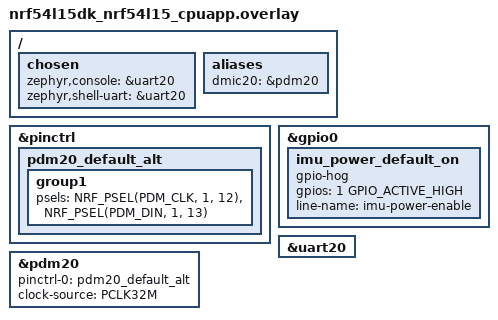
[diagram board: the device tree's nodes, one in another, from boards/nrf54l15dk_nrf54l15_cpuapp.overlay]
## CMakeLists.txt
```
# SPDX-License-Identifier: Apache-2.0

cmake_minimum_required(VERSION 3.20.0)

# Find Zephyr
find_package(Zephyr REQUIRED HINTS $ENV{ZEPHYR_BASE})

# Create project
project(voice_bridge_ble)

# Target sources
target_sources(app PRIVATE
    src/main.c
    src/adpcm.c
    src/audio_capture.c
)
```

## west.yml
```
manifest:
  version: 1.0

  defaults:
    remote: upstream
    revision: v4.0.0

  remotes:
    - name: upstream
      url-base: https://github.com/zephyrproject-rtos

  projects:
    - name: zephyr
      repo-path: zephyr
      path: zephyr
      import:
        name-allowlist:
          - hal_nordic
          - mcuboot
          - trusted-firmware-m

  self:
    path: nrf54l15
```

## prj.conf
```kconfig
# Zephyr Kernel Configuration for Voice Bridge BLE
# nRF54L15 Sense - BLE with PDM Microphone

# General System
CONFIG_MAIN_STACK_SIZE=4096
CONFIG_HEAP_MEM_POOL_SIZE=49152
CONFIG_SYS_CLOCK_TICKS_PER_SEC=32768

# Logging & Console
CONFIG_LOG=y
CONFIG_LOG_MODE_DEFERRED=n
CONFIG_CONSOLE=y
CONFIG_UART_CONSOLE=y
CONFIG_PRINTK=y

# Bluetooth Low Energy
CONFIG_BT=y
CONFIG_BT_PERIPHERAL=y
CONFIG_BT_BROADCASTER=y
CONFIG_BT_MAX_CONN=2
CONFIG_BT_SMP=n
CONFIG_BT_GATT_DYNAMIC_DB=y
CONFIG_BT_DEVICE_NAME="VoiceBridge"
CONFIG_BT_DEVICE_NAME_DYNAMIC=y
CONFIG_BT_DEVICE_NAME_MAX=20

# GATT client (for MTU exchange)
CONFIG_BT_GATT_CLIENT=y

# MTU extension for audio throughput
CONFIG_BT_L2CAP_TX_MTU=247
CONFIG_BT_BUF_ACL_RX_SIZE=251
CONFIG_BT_BUF_ACL_TX_SIZE=251
CONFIG_BT_CTLR_DATA_LENGTH_MAX=251

# Multiple TX buffers for throughput
CONFIG_BT_L2CAP_TX_BUF_COUNT=10
CONFIG_BT_ATT_TX_COUNT=10
CONFIG_BT_CONN_TX_MAX=10

# GPIO
CONFIG_GPIO=y
CONFIG_GPIO_NRFX=y

# PDM Microphone (DMIC)
CONFIG_AUDIO=y
CONFIG_AUDIO_DMIC=y
CONFIG_PINCTRL=y
```

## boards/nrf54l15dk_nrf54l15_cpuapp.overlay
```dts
/*
 * Device Tree Overlay for Voice Bridge BLE
 * PDM Microphone on XIAO nRF54L15 Sense
 * PDM_CLK: P1.12, PDM_DATA: P1.13
 */

#include <dt-bindings/gpio/gpio.h>

/ {
	chosen {
		zephyr,console = &uart20;
		zephyr,shell-uart = &uart20;
	};

	aliases {
		dmic20 = &pdm20;
	};
};

&pinctrl {
	pdm20_default_alt: pdm20_default_alt {
		group1 {
			psels = <NRF_PSEL(PDM_CLK, 1, 12)>,
				<NRF_PSEL(PDM_DIN, 1, 13)>;
		};
	};
};

&gpio0 {
	imu_power_default_on: imu_power_default_on {
		gpio-hog;
		gpios = <1 GPIO_ACTIVE_HIGH>;
		line-name = "imu-power-enable";
	};
};

&uart20 {
	status = "okay";
};

dmic_dev: &pdm20 {
	status = "okay";
	pinctrl-0 = <&pdm20_default_alt>;
	pinctrl-names = "default";
	clock-source = "PCLK32M";
};
```

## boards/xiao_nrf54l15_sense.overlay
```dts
/*
 * Device Tree Overlay for Seeed Studio XIAO nRF54L15 Sense
 * Voice Bridge BLE - PDM Microphone Configuration
 */

#include <dt-bindings/gpio/gpio.h>

/ {
    chosen {
        zephyr,console = &uart20;
        zephyr,shell-uart = &uart20;
    };

    aliases {
        dmic20 = &pdm20;
    };
};

&pinctrl {
    pdm20_default_alt: pdm20_default_alt {
        group1 {
            psels = <NRF_PSEL(PDM_CLK, 1, 12)>,
                    <NRF_PSEL(PDM_DIN, 1, 13)>;
        };
    };
};

&gpio0 {
    imu_power_default_on: imu_power_default_on {
        gpio-hog;
        gpios = <1 GPIO_ACTIVE_HIGH>;
        line-name = "imu-power-enable";
    };
};

/* PDM instance 20 for onboard DMIC microphone */
&pdm20 {
    status = "okay";
    pinctrl-0 = <&pdm20_default_alt>;
    pinctrl-names = "default";
    clock-source = "PCLK32M";
};

&uart20 {
    status = "okay";
};
```

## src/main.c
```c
/*
 * Voice Bridge BLE - XIAO nRF54L15 Sense
 * PDM Microphone to Mac via BLE
 */

#include <zephyr/kernel.h>
#include <zephyr/logging/log.h>
#include <zephyr/bluetooth/bluetooth.h>
#include <zephyr/bluetooth/conn.h>
#include <zephyr/bluetooth/uuid.h>
#include <zephyr/bluetooth/gatt.h>
#include <string.h>

#include "audio_capture.h"

LOG_MODULE_REGISTER(voice_bridge, LOG_LEVEL_INF);

/* ============================================================================
 * Configuration
 * ============================================================================ */

#define BLE_DEVICE_NAME     "VoiceBridge"

/* Recording packet size */
#define PCM_PACKET_SIZE     200

/* ============================================================================
 * BLE UUIDs (Same as ESP32/nRF52840 version for compatibility)
 * ============================================================================ */

/* Custom Service UUID: 00000001-0000-1000-8000-00805f9b34fb */
#define LBS_UUID_SERVICE \
    0xfb, 0x34, 0x9b, 0x5f, 0x80, 0x00, 0x00, 0x80, \
    0x00, 0x10, 0x00, 0x00, 0x01, 0x00, 0x00, 0x00

/* TX Characteristic UUID: 00000002-0000-1000-8000-00805f9b34fb (Notify) */
#define LBS_UUID_TX_CHAR \
    0xfb, 0x34, 0x9b, 0x5f, 0x80, 0x00, 0x00, 0x80, \
    0x00, 0x10, 0x00, 0x00, 0x02, 0x00, 0x00, 0x00

/* RX Characteristic UUID: 00000003-0000-1000-8000-00805f9b34fb (Write) */
#define LBS_UUID_RX_CHAR \
    0xfb, 0x34, 0x9b, 0x5f, 0x80, 0x00, 0x00, 0x80, \
    0x00, 0x10, 0x00, 0x00, 0x03, 0x00, 0x00, 0x00

/* ============================================================================
 * Global Variables
 * ============================================================================ */

static struct bt_conn *current_conn;

static uint8_t tx_packet[512];  /* PCM frame + 2-byte header */
static uint8_t seq_num = 0;

/* Recording state */
static volatile bool is_recording = false;
static volatile bool recording_requested = false;
static volatile bool stop_requested = false;

/* Audio thread */
static K_THREAD_STACK_DEFINE(audio_stack, 4096);
static struct k_thread audio_thread_data;
static void stream_audio_frame(const int16_t *audio_buffer, size_t audio_size);

static void generate_simulated_audio(int16_t *buffer, size_t sample_count)
{
    static uint32_t phase;
    const uint32_t freq = 440;
    const uint32_t sample_rate = audio_capture_get_sample_rate();

    for (size_t i = 0; i < sample_count; i++) {
        int32_t angle = (phase & 0xFFFF) * 360 / 0x10000;
        int32_t sample;

        if (angle < 90) {
            sample = angle * angle / 81;
        } else if (angle < 180) {
            sample = 16384 - (angle - 90) * (angle - 90) / 81;
        } else if (angle < 270) {
            sample = -(angle - 180) * (angle - 180) / 81;
        } else {
            sample = -16384 + (angle - 270) * (angle - 270) / 81;
        }

        buffer[i] = (int16_t)(sample * 2);
        phase += (freq * 0x10000) / sample_rate;
    }
}

/* ============================================================================
 * BLE GATT Service
 * ============================================================================ */

/* TX Value Changed Callback */
static void tx_ccc_cfg_changed(const struct bt_gatt_attr *attr, uint16_t value)
{
    LOG_INF("TX CCCD updated: %d", value);
    printk(">>> CCCD updated: %d (1=notify enabled)\n", value);
}

/* RX Write Callback */
static ssize_t rx_write(struct bt_conn *conn, const struct bt_gatt_attr *attr,
                        const void *buf, uint16_t len, uint16_t offset,
                        uint8_t flags)
{
    const uint8_t *data = buf;

    LOG_INF("Received command: len=%d", len);
    printk(">>> RX write: len=%d\n", len);

    if (len >= 1) {
        if (data[0] == 0x01) {
            LOG_INF("Start recording command");
            printk(">>> START recording command received\n");
            recording_requested = true;
        } else if (data[0] == 0x00) {
            LOG_INF("Stop recording command");
            printk(">>> STOP recording command received\n");
            stop_requested = true;
        }
    }

    return len;
}

/* GATT Service Definition */
BT_GATT_SERVICE_DEFINE(voice_bridge_svc,
    BT_GATT_PRIMARY_SERVICE(
        BT_UUID_DECLARE_128(LBS_UUID_SERVICE)),

    /* TX Characteristic (Notify) */
    BT_GATT_CHARACTERISTIC(
        BT_UUID_DECLARE_128(LBS_UUID_TX_CHAR),
        BT_GATT_CHRC_NOTIFY,
        BT_GATT_PERM_READ,
        NULL, NULL, NULL),
    BT_GATT_CCC(tx_ccc_cfg_changed,
                BT_GATT_PERM_READ | BT_GATT_PERM_WRITE),

    /* RX Characteristic (Write) */
    BT_GATT_CHARACTERISTIC(
        BT_UUID_DECLARE_128(LBS_UUID_RX_CHAR),
        BT_GATT_CHRC_WRITE,
        BT_GATT_PERM_WRITE,
        NULL, rx_write, NULL),
);

static void stream_audio_frame(const int16_t *audio_buffer, size_t audio_size)
{
    int ret;
    size_t total_samples = audio_size / sizeof(int16_t);
    size_t offset = 0;
    size_t packets_sent = 0;
    size_t notify_errors = 0;

    while (offset < total_samples) {
        size_t samples_to_send = total_samples - offset;

        if (samples_to_send > PCM_PACKET_SIZE / sizeof(int16_t)) {
            samples_to_send = PCM_PACKET_SIZE / sizeof(int16_t);
        }

        tx_packet[0] = seq_num++;
        tx_packet[1] = 0xAA;
        memcpy(&tx_packet[2], &audio_buffer[offset],
               samples_to_send * sizeof(int16_t));

        ret = bt_gatt_notify(NULL, &voice_bridge_svc.attrs[2],
                             tx_packet, 2 + (samples_to_send * sizeof(int16_t)));
        if (ret == -ENOMEM) {
            k_msleep(1);
            ret = bt_gatt_notify(NULL, &voice_bridge_svc.attrs[2],
                                 tx_packet, 2 + (samples_to_send * sizeof(int16_t)));
        }

        if (ret == 0) {
            packets_sent++;
        } else {
            notify_errors++;
            printk("!!! bt_gatt_notify error: %d\n", ret);
        }

        offset += samples_to_send;
        k_msleep(1);
    }

    printk("Audio: %zu samples, sent %zu packets, errors %zu\n",
           total_samples, packets_sent, notify_errors);
}

/* ============================================================================
 * Audio Streaming Thread
 * ============================================================================ */

static void audio_thread(void *p1, void *p2, void *p3)
{
    ARG_UNUSED(p1);
    ARG_UNUSED(p2);
    ARG_UNUSED(p3);

    int ret;
    int16_t *audio_buffer;
    size_t audio_size;
    bool dmic_available = false;
    bool dmic_session_active = false;
    static int16_t sim_buffer[320];

    printk("Audio thread started\n");

    /* Initialize audio capture */
    ret = audio_capture_init();
    if (ret < 0) {
        printk("Audio init failed: %d\n", ret);
        printk(">>> Using simulated audio data\n");
    } else {
        dmic_available = true;
        printk("Audio capture initialized\n");
    }

    while (1) {
        if (recording_requested && !is_recording) {
            recording_requested = false;
            stop_requested = false;
            seq_num = 0;

            if (dmic_available) {
                ret = audio_capture_start();
                if (ret < 0) {
                    printk("Audio start failed: %d\n", ret);
                    printk(">>> Falling back to simulated audio\n");
                    dmic_session_active = false;
                } else {
                    dmic_session_active = true;
                    printk("Audio capture running\n");
                }
            }

            is_recording = true;
            printk("Recording started\n");
        }

        if (stop_requested && is_recording) {
            stop_requested = false;
            is_recording = false;

            if (dmic_session_active) {
                ret = audio_capture_stop();
                if (ret < 0) {
                    printk("Audio stop failed: %d\n", ret);
                }
                dmic_session_active = false;
            }

            printk("Recording stopped\n");
        }

        if (is_recording && current_conn) {
            if (dmic_session_active) {
                ret = audio_capture_get_data(&audio_buffer, &audio_size);
                if (ret < 0) {
                    printk("Audio read failed: %d\n", ret);
                    printk(">>> Falling back to simulated audio\n");
                    (void)audio_capture_stop();
                    dmic_session_active = false;
                    continue;
                }
            } else {
                generate_simulated_audio(sim_buffer, ARRAY_SIZE(sim_buffer));
                audio_buffer = sim_buffer;
                audio_size = sizeof(sim_buffer);
            }

            stream_audio_frame(audio_buffer, audio_size);
            continue;
        }

        if (!current_conn && dmic_session_active) {
            (void)audio_capture_stop();
            dmic_session_active = false;
        }

        if (!is_recording) {
            k_msleep(20);
        } else {
            static int debug_count = 0;
            if (debug_count++ % 50 == 0 && !current_conn) {
                printk("DEBUG: Not connected (current_conn=NULL)\n");
            }
            k_msleep(20);
        }
    }
}

/* ============================================================================
 * BLE Connection Callbacks
 * ============================================================================ */

static void exchange_func(struct bt_conn *conn, uint8_t att_err,
                          struct bt_gatt_exchange_params *params)
{
    if (att_err) {
        LOG_ERR("MTU exchange failed: %d", att_err);
        printk(">>> MTU exchange failed: %d\n", att_err);
    } else {
        LOG_INF("MTU exchange done");
        printk(">>> MTU exchange done\n");
    }
}

static struct bt_gatt_exchange_params exchange_params = {
    .func = exchange_func,
};

static void connected(struct bt_conn *conn, uint8_t err)
{
    if (err) {
        LOG_ERR("Connection failed: %d", err);
        printk(">>> Connection failed: %d\n", err);
        return;
    }

    LOG_INF("Connected");
    printk(">>> Connected! current_conn set\n");
    current_conn = conn;

    /* Request MTU exchange */
    int ret = bt_gatt_exchange_mtu(conn, &exchange_params);
    if (ret) {
        LOG_ERR("MTU exchange request failed: %d", ret);
        printk(">>> MTU exchange failed: %d\n", ret);
    } else {
        printk(">>> MTU exchange requested\n");
    }

    /* Request short connection interval for audio throughput */
    struct bt_le_conn_param conn_param = {
        .interval_min = 6,   /* 7.5ms */
        .interval_max = 12,  /* 15ms */
        .latency = 0,
        .timeout = 400,      /* 4s */
    };
    ret = bt_conn_le_param_update(conn, &conn_param);
    if (ret) {
        LOG_WRN("Conn param update request failed: %d", ret);
        printk(">>> Conn param update failed: %d\n", ret);
    } else {
        printk(">>> Conn param update requested\n");
    }
}

static void disconnected(struct bt_conn *conn, uint8_t reason)
{
    LOG_INF("Disconnected: %d", reason);
    printk(">>> Disconnected: %d\n", reason);

    current_conn = NULL;

    is_recording = false;
    stop_requested = true;
}

static struct bt_conn_cb conn_callbacks = {
    .connected = connected,
    .disconnected = disconnected,
};

/* ============================================================================
 * Main Application
 * ============================================================================ */

int main(void)
{
    int ret;

    printk("\n");
    printk("============================================\n");
    printk("Voice Bridge BLE - XIAO nRF54L15 Sense\n");
    printk("============================================\n\n");
    printk("Starting firmware build: " __DATE__ " " __TIME__ "\n");

    LOG_INF("Starting Voice Bridge BLE");

    /* Initialize BLE (synchronous - pass NULL callback) */
    LOG_INF("Initializing BLE");
    ret = bt_enable(NULL);
    if (ret) {
        LOG_ERR("BLE enable failed: %d", ret);
        printk("!!! BLE enable failed: %d\n", ret);
        return ret;
    }

    LOG_INF("BLE initialized");
    printk("BLE initialized\n");

    /* Register connection callbacks */
    bt_conn_cb_register(&conn_callbacks);

    /* Set device name */
    ret = bt_set_name(BLE_DEVICE_NAME);
    if (ret) {
        LOG_ERR("Failed to set name: %d", ret);
        printk("!!! Failed to set name: %d\n", ret);
        return ret;
    }

    printk("Device name: %s\n", BLE_DEVICE_NAME);

    /* Start advertising */
    struct bt_data adv_data[] = {
        BT_DATA_BYTES(BT_DATA_FLAGS, BT_LE_AD_GENERAL | BT_LE_AD_NO_BREDR),
        BT_DATA_BYTES(BT_DATA_UUID128_ALL,
                     0xfb, 0x34, 0x9b, 0x5f, 0x80, 0x00, 0x00, 0x80,
                     0x00, 0x10, 0x00, 0x00, 0x01, 0x00, 0x00, 0x00),
    };

    struct bt_data scan_rsp[] = {
        BT_DATA(BT_DATA_NAME_COMPLETE, BLE_DEVICE_NAME, sizeof(BLE_DEVICE_NAME) - 1),
    };

    ret = bt_le_adv_start(BT_LE_ADV_CONN, adv_data, ARRAY_SIZE(adv_data),
                          scan_rsp, ARRAY_SIZE(scan_rsp));
    if (ret) {
        LOG_ERR("Advertising failed: %d", ret);
        printk("!!! Advertising failed: %d\n", ret);
        return ret;
    }

    LOG_INF("Advertising started: %s", BLE_DEVICE_NAME);
    printk("Advertising: %s\n", BLE_DEVICE_NAME);

    /* Start audio thread */
    /* Priority 14: lower than BLE stack (7) to avoid starving radio */
    k_thread_create(&audio_thread_data, audio_stack, K_THREAD_STACK_SIZEOF(audio_stack),
                    audio_thread, NULL, NULL, NULL, 14, 0, K_NO_WAIT);

    LOG_INF("Voice Bridge BLE ready");
    printk("System ready\n");

    /* Keep main thread alive */
    while (1) {
        k_sleep(K_SECONDS(1));
    }

    return 0;
}
```

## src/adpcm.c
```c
/*
 * ADPCM Codec Implementation
 * IMA ADPCM 4-bit encoding/decoding
 */

#include "adpcm.h"
#include <string.h>

/* IMA ADPCM step size table */
static const int32_t step_size_table[89] = {
    7, 8, 9, 10, 11, 12, 13, 14, 16, 17, 19, 21, 23, 25, 28, 31,
    34, 37, 41, 45, 50, 55, 60, 66, 73, 80, 88, 97, 107, 118, 130, 143,
    157, 173, 190, 209, 230, 253, 279, 307, 337, 371, 408, 449, 494, 544,
    598, 658, 724, 796, 876, 963, 1060, 1166, 1282, 1411, 1552, 1707, 1878,
    2066, 2272, 2499, 2749, 3024, 3327, 3660, 4026, 4428, 4871, 5358, 5894,
    6484, 7132, 7845, 8630, 9493, 10442, 11487, 12635, 13899, 15289, 16818,
    18500, 20350, 22385, 24623, 27086, 29794, 32767
};

/* Step size adjustment table for each ADPCM value */
static const int8_t step_adjust_table[8] = {
    -1, -1, -1, -1, 2, 4, 6, 8
};

static int32_t clamp(int32_t value, int32_t min, int32_t max)
{
    if (value < min) return min;
    if (value > max) return max;
    return value;
}

void adpcm_init_state(adpcm_state_t *state)
{
    state->predictor = 0;
    state->step_size = 7;  /* Initial step size */
}

size_t adpcm_encode(adpcm_state_t *state, const int16_t *input,
                    size_t num_samples, uint8_t *output)
{
    if (num_samples == 0 || input == NULL || output == NULL) {
        return 0;
    }

    int32_t predictor = state->predictor;
    int32_t step_size = state->step_size;

    size_t output_index = 0;
    uint8_t current_byte = 0;

    for (size_t i = 0; i < num_samples; i++) {
        /* Calculate difference */
        int32_t diff = (int32_t)input[i] - predictor;
        int8_t sign = (diff < 0) ? 1 : 0;

        if (diff < 0) {
            diff = -diff;
        }

        /* Calculate ADPCM value (0-7) */
        int8_t adpcm_value = 0;
        int32_t delta = step_size >> 3;  /* step_size / 8 */

        if (diff > delta) {
            adpcm_value = 1;
            diff -= delta;
            delta = step_size >> 2;  /* step_size / 4 */

            if (diff > delta) {
                adpcm_value = 2;
                diff -= delta;
                delta = step_size >> 1;  /* step_size / 2 */

                if (diff > delta) {
                    adpcm_value = 3;
                    diff -= delta;
                    delta = step_size;

                    if (diff > delta) {
                        adpcm_value = 4;
                        diff -= delta;
                    }
                }
            }
        }

        /* Combine sign and value */
        adpcm_value = (sign << 3) | adpcm_value;

        /* Update predictor */
        int32_t step = step_size;
        if (adpcm_value & 0x04) step += step_size >> 2;
        if (adpcm_value & 0x02) step += step_size >> 1;
        if (adpcm_value & 0x01) step += step_size >> 3;

        if (sign) {
            predictor -= step;
        } else {
            predictor += step;
        }

        /* Clamp predictor to 16-bit range */
        predictor = clamp(predictor, -32768, 32767);

        /* Update step size */
        int8_t index_change = step_adjust_table[adpcm_value & 0x07];
        int32_t new_step_index = 0;

        /* Find current step index */
        for (int32_t j = 0; j < 89; j++) {
            if (step_size_table[j] >= step_size) {
                new_step_index = j;
                break;
            }
        }

        new_step_index += index_change;
        new_step_index = clamp(new_step_index, 0, 88);
        step_size = step_size_table[new_step_index];

        /* Pack two 4-bit ADPCM values into one byte */
        if (i % 2 == 0) {
            current_byte = (adpcm_value & 0x0F);
        } else {
            current_byte |= ((adpcm_value & 0x0F) << 4);
            output[output_index++] = current_byte;
        }
    }

    /* Handle odd number of samples */
    if (num_samples % 2 != 0) {
        output[output_index++] = current_byte;
    }

    /* Save state */
    state->predictor = predictor;
    state->step_size = step_size;

    return output_index;
}

size_t adpcm_decode(adpcm_state_t *state, const uint8_t *input,
                    size_t num_bytes, int16_t *output)
{
    if (num_bytes == 0 || input == NULL || output == NULL) {
        return 0;
    }

    int32_t predictor = state->predictor;
    int32_t step_size = state->step_size;

    size_t output_index = 0;

    for (size_t i = 0; i < num_bytes; i++) {
        /* Process two 4-bit values per byte */
        for (int nibble = 0; nibble < 2; nibble++) {
            uint8_t adpcm_value = (input[i] >> (nibble * 4)) & 0x0F;

            /* Extract sign and value */
            int8_t sign = (adpcm_value >> 3) & 0x01;
            uint8_t value = adpcm_value & 0x07;

            /* Calculate step */
            int32_t step = step_size;
            if (value & 0x04) step += step_size >> 2;
            if (value & 0x02) step += step_size >> 1;
            if (value & 0x01) step += step_size >> 3;

            /* Update predictor */
            if (sign) {
                predictor -= step;
            } else {
                predictor += step;
            }

            /* Clamp predictor to 16-bit range */
            predictor = clamp(predictor, -32768, 32767);

            /* Update step size */
            int8_t index_change = step_adjust_table[value];
            int32_t new_step_index = 0;

            /* Find current step index */
            for (int32_t j = 0; j < 89; j++) {
                if (step_size_table[j] >= step_size) {
                    new_step_index = j;
                    break;
                }
            }

            new_step_index += index_change;
            new_step_index = clamp(new_step_index, 0, 88);
            step_size = step_size_table[new_step_index];

            /* Output decoded sample */
            output[output_index++] = (int16_t)predictor;
        }
    }

    /* Save state */
    state->predictor = predictor;
    state->step_size = step_size;

    return output_index;
}
```

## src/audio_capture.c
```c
/*
 * Audio Capture for Voice Bridge BLE
 * PDM Microphone via Zephyr DMIC API on nRF54L15
 */

#include <zephyr/kernel.h>
#include <zephyr/device.h>
#include <zephyr/audio/dmic.h>
#include <zephyr/logging/log.h>

#include "audio_capture.h"

LOG_MODULE_REGISTER(audio_capture, LOG_LEVEL_INF);

/* ============================================================================
 * Configuration
 * ============================================================================ */

#define SAMPLE_RATE         16000
#define SAMPLE_BITS         16
#define CHANNELS            1
#define BYTES_PER_SAMPLE    sizeof(int16_t)

/* 20ms frame = 320 samples = 640 bytes */
#define FRAME_MS            20
#define FRAME_SAMPLES       (SAMPLE_RATE * FRAME_MS / 1000)
#define FRAME_BYTES         (FRAME_SAMPLES * BYTES_PER_SAMPLE * CHANNELS)

/* Memory slab for DMIC driver buffers */
#define BLOCK_COUNT         4
K_MEM_SLAB_DEFINE_STATIC(pdm_mem_slab, FRAME_BYTES, BLOCK_COUNT, 4);

/* ============================================================================
 * Global Variables
 * ============================================================================ */

static const struct device *dmic_dev;
static bool dmic_configured = false;
static bool dmic_started = false;

/* Current audio buffer from dmic_read */
static void *current_block = NULL;

/* ============================================================================
 * Public API
 * ============================================================================ */

int audio_capture_init(void)
{
    if (dmic_configured) {
        return 0;
    }

#ifdef DT_N_ALIAS_dmic20
    dmic_dev = DEVICE_DT_GET(DT_ALIAS(dmic20));
#else
    dmic_dev = DEVICE_DT_GET(DT_NODELABEL(pdm20));
#endif
    if (!device_is_ready(dmic_dev)) {
        LOG_ERR("DMIC device not ready: %s", dmic_dev->name);
        printk("!!! DMIC device not ready: %s\n", dmic_dev->name);
        return -ENODEV;
    }

    struct pcm_stream_cfg stream = {
        .pcm_width = SAMPLE_BITS,
        .pcm_rate  = SAMPLE_RATE,
        .block_size = FRAME_BYTES,
        .mem_slab  = &pdm_mem_slab,
    };

    struct dmic_cfg cfg = {
        .io = {
            .min_pdm_clk_freq = 1000000,
            .max_pdm_clk_freq = 3500000,
            .min_pdm_clk_dc   = 40,
            .max_pdm_clk_dc   = 60,
        },
        .streams = &stream,
        .channel = {
            .req_num_streams = 1,
            .req_num_chan = CHANNELS,
            .req_chan_map_lo = dmic_build_channel_map(0, 0, PDM_CHAN_LEFT),
        },
    };

    int ret = dmic_configure(dmic_dev, &cfg);
    if (ret < 0) {
        LOG_ERR("DMIC configure failed: %d", ret);
        printk("!!! DMIC configure failed: %d\n", ret);
        return ret;
    }

    dmic_configured = true;
    LOG_INF("Audio capture initialized: %d Hz, %d-bit, %d ch, %d ms frames",
            SAMPLE_RATE, SAMPLE_BITS, CHANNELS, FRAME_MS);
    printk("Audio init OK: %d Hz, %d samples/frame\n", SAMPLE_RATE, FRAME_SAMPLES);
    return 0;
}

int audio_capture_start(void)
{
    if (!dmic_configured) {
        return -EIO;
    }

    if (dmic_started) {
        return 0;
    }

    int ret = dmic_trigger(dmic_dev, DMIC_TRIGGER_START);
    if (ret < 0) {
        LOG_ERR("DMIC start failed: %d", ret);
        printk("!!! DMIC start failed: %d\n", ret);
        return ret;
    }

    dmic_started = true;
    LOG_INF("Audio capture started");
    printk("Audio started\n");

    void *discard_block = NULL;
    uint32_t discard_size;

    ret = dmic_read(dmic_dev, 0, &discard_block, &discard_size, 1000);
    if (ret == 0 && discard_block != NULL) {
        k_mem_slab_free(&pdm_mem_slab, discard_block);
    } else if (ret < 0) {
        LOG_WRN("Initial DMIC discard read failed: %d", ret);
    }

    return 0;
}

int audio_capture_stop(void)
{
    if (!dmic_started) {
        return 0;
    }

    int ret = dmic_trigger(dmic_dev, DMIC_TRIGGER_STOP);
    if (ret < 0) {
        LOG_ERR("DMIC stop failed: %d", ret);
        return ret;
    }

    /* Free any pending block */
    if (current_block) {
        k_mem_slab_free(&pdm_mem_slab, current_block);
        current_block = NULL;
    }

    dmic_started = false;
    LOG_INF("Audio capture stopped");
    return 0;
}

int audio_capture_get_data(int16_t **buffer, size_t *size)
{
    if (!dmic_started) {
        return -EAGAIN;
    }

    /* Free previous block if any */
    if (current_block) {
        k_mem_slab_free(&pdm_mem_slab, current_block);
        current_block = NULL;
    }

    uint32_t read_size;
    int ret = dmic_read(dmic_dev, 0, &current_block, &read_size, 200);
    if (ret < 0) {
        LOG_WRN("DMIC read failed: %d", ret);
        return ret;
    }

    if (buffer) {
        *buffer = (int16_t *)current_block;
    }
    if (size) {
        *size = read_size;
    }

    return 0;
}

size_t audio_capture_get_frame_size(void)
{
    return FRAME_BYTES;
}

uint32_t audio_capture_get_sample_rate(void)
{
    return SAMPLE_RATE;
}
```

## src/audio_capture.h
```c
/*
 * Audio Capture Module for Voice Bridge BLE
 * PDM Microphone interface using Zephyr Audio Subsystem
 */

#ifndef AUDIO_CAPTURE_H
#define AUDIO_CAPTURE_H

#include <stdint.h>
#include <stddef.h>

#ifdef __cplusplus
extern "C" {
#endif

/**
 * Initialize audio capture from PDM microphone
 * 
 * @return 0 on success, negative errno on failure
 */
int audio_capture_init(void);

/**
 * Start audio capture
 * 
 * @return 0 on success, negative errno on failure
 */
int audio_capture_start(void);

/**
 * Stop audio capture
 * 
 * @return 0 on success, negative errno on failure
 */
int audio_capture_stop(void);

/**
 * Get audio data from capture buffer
 * 
 * @param buffer Pointer to receive buffer pointer
 * @param size Pointer to receive data size
 * @return 0 on success, negative errno on failure
 */
int audio_capture_get_data(int16_t **buffer, size_t *size);

/**
 * Get frame size in bytes
 * 
 * @return Frame size
 */
size_t audio_capture_get_frame_size(void);

/**
 * Get sample rate
 * 
 * @return Sample rate in Hz
 */
uint32_t audio_capture_get_sample_rate(void);

#ifdef __cplusplus
}
#endif

#endif /* AUDIO_CAPTURE_H */
```
